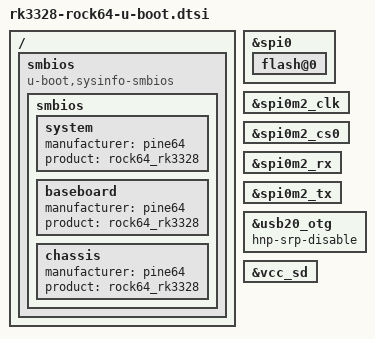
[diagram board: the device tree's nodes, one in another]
// SPDX-License-Identifier: GPL-2.0+
/*
 * (C) Copyright 2018-2019 Rockchip Electronics Co., Ltd
 */

#include "rk3328-u-boot.dtsi"
#include "rk3328-sdram-lpddr3-1600.dtsi"

/ {
	smbios {
		compatible = "u-boot,sysinfo-smbios";

		smbios {
			system {
				manufacturer = "pine64";
				product = "rock64_rk3328";
			};

			baseboard {
				manufacturer = "pine64";
				product = "rock64_rk3328";
			};

			chassis {
				manufacturer = "pine64";
				product = "rock64_rk3328";
			};
		};
	};
};

&spi0 {
	flash@0 {
		bootph-pre-ram;
		bootph-some-ram;
	};
};

&spi0m2_clk {
	bootph-pre-ram;
	bootph-some-ram;
};

&spi0m2_cs0 {
	bootph-pre-ram;
	bootph-some-ram;
};

&spi0m2_rx {
	bootph-pre-ram;
	bootph-some-ram;
};

&spi0m2_tx {
	bootph-pre-ram;
	bootph-some-ram;
};

&usb20_otg {
	hnp-srp-disable;
};

&vcc_sd {
	bootph-pre-ram;
};
